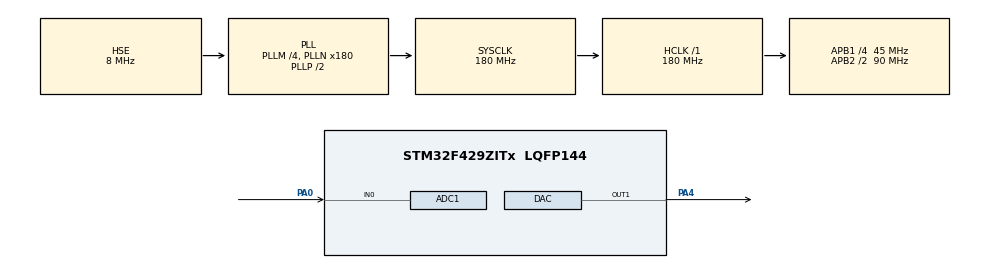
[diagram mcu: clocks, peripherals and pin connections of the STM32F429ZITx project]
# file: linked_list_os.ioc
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ADC1.Channel-0\#ChannelRegularConversion=ADC_CHANNEL_0
ADC1.DMAContinuousRequests=ENABLE
ADC1.ExternalTrigConv=ADC_EXTERNALTRIGCONV_T8_TRGO
ADC1.NbrOfConversionFlag=1
ADC1.Rank-0\#ChannelRegularConversion=1
ADC1.SamplingTime-0\#ChannelRegularConversion=ADC_SAMPLETIME_144CYCLES
ADC1.master=1
DAC.DAC_Trigger=DAC_TRIGGER_T2_TRGO
DAC.WaveGeneration=DISABLE
Dma.ADC1.0.Direction=DMA_PERIPH_TO_MEMORY
Dma.ADC1.0.FIFOMode=DMA_FIFOMODE_DISABLE
Dma.ADC1.0.Instance=DMA2_Stream0
Dma.ADC1.0.MemDataAlignment=DMA_MDATAALIGN_HALFWORD
Dma.ADC1.0.MemInc=DMA_MINC_ENABLE
Dma.ADC1.0.Mode=DMA_CIRCULAR
Dma.ADC1.0.PeriphDataAlignment=DMA_PDATAALIGN_HALFWORD
Dma.ADC1.0.PeriphInc=DMA_PINC_DISABLE
Dma.ADC1.0.Priority=DMA_PRIORITY_LOW
Dma.DAC1.1.Direction=DMA_MEMORY_TO_PERIPH
Dma.DAC1.1.FIFOMode=DMA_FIFOMODE_DISABLE
Dma.DAC1.1.Instance=DMA1_Stream5
Dma.DAC1.1.MemDataAlignment=DMA_MDATAALIGN_HALFWORD
Dma.DAC1.1.MemInc=DMA_MINC_ENABLE
Dma.DAC1.1.Mode=DMA_CIRCULAR
Dma.DAC1.1.PeriphDataAlignment=DMA_PDATAALIGN_HALFWORD
Dma.DAC1.1.PeriphInc=DMA_PINC_DISABLE
Dma.DAC1.1.Priority=DMA_PRIORITY_VERY_HIGH
Dma.Request0=ADC1
Dma.Request1=DAC1
Mcu.Family=STM32F4
Mcu.Name=STM32F429ZITx
Mcu.Package=LQFP144
NVIC.DMA1_Stream5_IRQn=true\:0\:0\:false\:false\:true\:false\:true\:true
NVIC.DMA2_Stream0_IRQn=true\:0\:0\:false\:false\:true\:false\:true\:true
NVIC.PriorityGroup=NVIC_PRIORITYGROUP_4
NVIC.TIM1_UP_TIM10_IRQn=true\:15\:0\:false\:false\:true\:false\:true\:true
NVIC.TimeBase=TIM1_UP_TIM10_IRQn
NVIC.TimeBaseIP=TIM1
PA0/WKUP.Signal=ADCx_IN0
PA13.Mode=Serial_Wire
PA13.Signal=SYS_JTMS-SWDIO
PA14.Mode=Serial_Wire
PA14.Signal=SYS_JTCK-SWCLK
PA4.Signal=COMP_DAC1_group
PH0/OSC_IN.Mode=HSE-External-Oscillator
PH0/OSC_IN.Signal=RCC_OSC_IN
PH1/OSC_OUT.Mode=HSE-External-Oscillator
PH1/OSC_OUT.Signal=RCC_OSC_OUT
ProjectManager.HeapSize=0x200
ProjectManager.StackSize=0x400
ProjectManager.TargetToolchain=STM32CubeIDE
RCC.48MHZClocksFreq_Value=90000000
RCC.AHBFreq_Value=180000000
RCC.APB1CLKDivider=RCC_HCLK_DIV4
RCC.APB1Freq_Value=45000000
RCC.APB1TimFreq_Value=90000000
RCC.APB2CLKDivider=RCC_HCLK_DIV2
RCC.APB2Freq_Value=90000000
RCC.APB2TimFreq_Value=180000000
RCC.CortexFreq_Value=180000000
RCC.HCLKFreq_Value=180000000
RCC.HSE_VALUE=8000000
RCC.HSI_VALUE=16000000
RCC.LSE_VALUE=32768
RCC.PLLM=4
RCC.PLLN=180
RCC.PLLSourceVirtual=RCC_PLLSOURCE_HSE
RCC.SYSCLKFreq_VALUE=180000000
RCC.SYSCLKSource=RCC_SYSCLKSOURCE_PLLCLK
RCC.VCOOutputFreq_Value=360000000
SH.ADCx_IN0.0=ADC1_IN0,IN0
SH.COMP_DAC1_group.0=DAC_OUT1,DAC_OUT1
TIM2.AutoReloadPreload=TIM_AUTORELOAD_PRELOAD_ENABLE
TIM2.Period=5859
TIM2.TIM_MasterOutputTrigger=TIM_TRGO_UPDATE
TIM2.TIM_MasterSlaveMode=TIM_MASTERSLAVEMODE_ENABLE
TIM8.AutoReloadPreload=TIM_AUTORELOAD_PRELOAD_ENABLE
TIM8.Period=11719
TIM8.TIM_MasterOutputTrigger=TIM_TRGO_UPDATE
TIM8.TIM_MasterSlaveMode=TIM_MASTERSLAVEMODE_ENABLE
VP_SYS_VS_tim1.Mode=TIM1
VP_TIM2_VS_ClockSourceINT.Mode=Internal
VP_TIM8_VS_ClockSourceINT.Mode=Internal
board=custom

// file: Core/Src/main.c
/* USER CODE BEGIN Header */
/**
  ******************************************************************************
  * @file           : main.c
  * @brief          : Main program body
  ******************************************************************************
  * @attention
  *
  * Copyright (c) 2022 STMicroelectronics.
  * All rights reserved.
  *
  * This software is licensed under terms that can be found in the LICENSE file
  * in the root directory of this software component.
  * If no LICENSE file comes with this software, it is provided AS-IS.
  *
  ******************************************************************************
  */
/* USER CODE END Header */
#include "main.h"

/* USER CODE BEGIN Includes */
#include "os.h"
#include "arm_const_structs.h"
/* USER CODE END Includes */

ADC_HandleTypeDef hadc1;
DMA_HandleTypeDef hdma_adc1;

DAC_HandleTypeDef hdac;
DMA_HandleTypeDef hdma_dac1;

TIM_HandleTypeDef htim2;
TIM_HandleTypeDef htim8;

void SystemClock_Config(void);
static void MX_GPIO_Init(void);
static void MX_DMA_Init(void);
static void MX_ADC1_Init(void);
static void MX_TIM8_Init(void);
static void MX_DAC_Init(void);
static void MX_TIM2_Init(void);

/* USER CODE BEGIN 0 */
#if 0
#define MEDIA_CALIB_POWER2 7
// Numero de Amostras sera 2^MEDIA_CALIB_POWER2
#define MEDIA_CALIB_SIZE (1<<MEDIA_CALIB_POWER2)
unsigned int DR1 = 0;
static void MX_ADCalibration_Init(void)
{

  ADC_MultiModeTypeDef multimode;
  ADC_ChannelConfTypeDef sConfig;

    /**Configure the global features of the ADC (Clock, Resolution, Data Alignment and number of conversion)
    */
  hadc1.Instance = ADC1;
  hadc1.Init.ClockPrescaler = ADC_CLOCK_SYNC_PCLK_DIV4;
  hadc1.Init.Resolution = ADC_RESOLUTION_12B;
  hadc1.Init.ScanConvMode = DISABLE;
  hadc1.Init.ContinuousConvMode = ENABLE;
  hadc1.Init.DiscontinuousConvMode = DISABLE;
  hadc1.Init.ExternalTrigConvEdge = ADC_EXTERNALTRIGCONVEDGE_NONE ;
  hadc1.Init.ExternalTrigConv = 0;
  hadc1.Init.DataAlign = ADC_DATAALIGN_RIGHT;
  hadc1.Init.NbrOfConversion = 1;
  hadc1.Init.DMAContinuousRequests = DISABLE;
  hadc1.Init.EOCSelection = ADC_EOC_SINGLE_CONV;
  if (HAL_ADC_Init(&hadc1) != HAL_OK)
  {
	  Error_Handler();
  }

    /**Configure the ADC multi-mode
    */
  multimode.Mode = ADC_MODE_INDEPENDENT ;
  multimode.DMAAccessMode = ADC_DMAACCESSMODE_DISABLED;
  multimode.TwoSamplingDelay = ADC_TWOSAMPLINGDELAY_5CYCLES;
  if (HAL_ADCEx_MultiModeConfigChannel(&hadc1, &multimode) != HAL_OK)
  {
	  Error_Handler();
  }

    /**Configure for the selected ADC regular channel its corresponding rank in the sequencer and its sample time.
    */
  sConfig.Channel = ADC_CHANNEL_VREFINT;
  sConfig.Rank = 1;
  sConfig.SamplingTime = ADC_SAMPLETIME_480CYCLES;
  if (HAL_ADC_ConfigChannel(&hadc1, &sConfig) != HAL_OK)
  {
	  Error_Handler();
  }

  HAL_ADC_Start(&hadc1);

  unsigned int n=0;

  for(n=0;n<MEDIA_CALIB_SIZE;n++){

	HAL_ADC_PollForConversion(&hadc1, HAL_MAX_DELAY);

	DR1 += hadc1.Instance->DR;

  }
	HAL_ADC_Stop(&hadc1);
	HAL_ADC_DeInit(&hadc1);
	DR1 = DR1 >> MEDIA_CALIB_POWER2;

}

FC=1.21/(Get_ADC_Calib());

unsigned int Get_ADC_Calib (void){
	return DR1;
}
#endif

tcb_t task1_tcb;
cpu_t task1_stk[512];

tcb_t task2_tcb;
cpu_t task2_stk[128];

uint16_t adcBuffer[256];
float ReIm[256*2];
float mod[256];
sem_t sem;

uint16_t sin_wave[256] = {2048, 2098, 2148, 2199, 2249, 2299, 2349, 2399, 2448, 2498, 2547, 2596, 2644, 2692, 2740,
		2787, 2834, 2880, 2926, 2971, 3016, 3060, 3104, 3147, 3189, 3230, 3271, 3311, 3351, 3389,
		3427, 3464, 3500, 3535, 3569, 3602, 3635, 3666, 3697, 3726, 3754, 3782, 3808, 3833, 3857,
		3880, 3902, 3923, 3943, 3961, 3979, 3995, 4010, 4024, 4036, 4048, 4058, 4067, 4074, 4081,
		4086, 4090, 4093, 4095, 4095, 4094, 4092, 4088, 4084, 4078, 4071, 4062, 4053, 4042, 4030,
		4017, 4002, 3987, 3970, 3952, 3933, 3913, 3891, 3869, 3845, 3821, 3795, 3768, 3740, 3711,
		3681, 3651, 3619, 3586, 3552, 3517, 3482, 3445, 3408, 3370, 3331, 3291, 3251, 3210, 3168,
		3125, 3082, 3038, 2994, 2949, 2903, 2857, 2811, 2764, 2716, 2668, 2620, 2571, 2522, 2473,
		2424, 2374, 2324, 2274, 2224, 2174, 2123, 2073, 2022, 1972, 1921, 1871, 1821, 1771, 1721,
		1671, 1622, 1573, 1524, 1475, 1427, 1379, 1331, 1284, 1238, 1192, 1146, 1101, 1057, 1013,
		970, 927, 885, 844, 804, 764, 725, 687, 650, 613, 578, 543, 509, 476, 444,
		414, 384, 355, 327, 300, 274, 250, 226, 204, 182, 162, 143, 125, 108, 93,
		78, 65, 53, 42, 33, 24, 17, 11, 7, 3, 1, 0, 0, 2, 5,
		9, 14, 21, 28, 37, 47, 59, 71, 85, 100, 116, 134, 152, 172, 193,
		215, 238, 262, 287, 313, 341, 369, 398, 429, 460, 493, 526, 560, 595, 631,
		668, 706, 744, 784, 824, 865, 906, 948, 991, 1035, 1079, 1124, 1169, 1215, 1261,
		1308, 1355, 1403, 1451, 1499, 1548, 1597, 1647, 1696, 1746, 1796, 1846, 1896, 1947, 1997,
		2047};

uint16_t sin_wave_3rd_harmonic[256] = {2048, 2136, 2224, 2311, 2398, 2484, 2569, 2652, 2734, 2814, 2892, 2968, 3041, 3112, 3180,
		3245, 3308, 3367, 3423, 3476, 3526, 3572, 3615, 3654, 3690, 3723, 3752, 3778, 3800, 3819,
		3835, 3848, 3858, 3866, 3870, 3872, 3871, 3869, 3864, 3857, 3848, 3838, 3827, 3814, 3801,
		3786, 3771, 3756, 3740, 3725, 3709, 3694, 3679, 3665, 3652, 3639, 3628, 3617, 3608, 3600,
		3594, 3589, 3585, 3584, 3583, 3584, 3587, 3591, 3597, 3604, 3613, 3622, 3633, 3645, 3658,
		3672, 3686, 3701, 3717, 3732, 3748, 3764, 3779, 3794, 3808, 3821, 3833, 3844, 3853, 3860,
		3866, 3870, 3872, 3871, 3868, 3862, 3854, 3842, 3828, 3810, 3789, 3765, 3738, 3707, 3673,
		3635, 3594, 3549, 3501, 3450, 3396, 3338, 3277, 3213, 3146, 3077, 3005, 2930, 2853, 2774,
		2693, 2611, 2527, 2441, 2355, 2268, 2180, 2092, 2003, 1915, 1827, 1740, 1654, 1568, 1484,
		1402, 1321, 1242, 1165, 1090, 1018, 949, 882, 818, 757, 699, 645, 594, 546, 501,
		460, 422, 388, 357, 330, 306, 285, 267, 253, 241, 233, 227, 224, 223, 225,
		229, 235, 242, 251, 262, 274, 287, 301, 316, 331, 347, 363, 378, 394, 409,
		423, 437, 450, 462, 473, 482, 491, 498, 504, 508, 511, 512, 511, 510, 506,
		501, 495, 487, 478, 467, 456, 443, 430, 416, 401, 386, 370, 355, 339, 324,
		309, 294, 281, 268, 257, 247, 238, 231, 226, 224, 223, 225, 229, 237, 247,
		260, 276, 295, 317, 343, 372, 405, 441, 480, 523, 569, 619, 672, 728, 787,
		850, 915, 983, 1054, 1127, 1203, 1281, 1361, 1443, 1526, 1611, 1697, 1784, 1871, 1959,
		2047};

void HAL_ADC_ConvCpltCallback(ADC_HandleTypeDef* hadc){
	os_sem_post(&sem);
}

volatile int counter = 0;
volatile int flag = 0;
void HAL_DAC_ConvCpltCallbackCh1(DAC_HandleTypeDef* hadc){
	counter++;
	if (counter >= 120){
		counter = 0;
		HAL_TIM_Base_Stop(&htim2);
		HAL_DAC_Stop_DMA(&hdac, DAC_CHANNEL_1);

		if (flag == 0){
			HAL_DAC_Start_DMA(&hdac, DAC_CHANNEL_1, (uint32_t*)sin_wave_3rd_harmonic, 256, DAC_ALIGN_12B_R);
			flag = 1;
		}else{
			HAL_DAC_Start_DMA(&hdac, DAC_CHANNEL_1, (uint32_t*)sin_wave, 256, DAC_ALIGN_12B_R);
			flag = 0;
		}
	    HAL_TIM_Base_Start(&htim2);
	}
}

void task1(void){
	os_sem_init(&sem);

	HAL_ADC_Start_DMA(&hadc1, (uint32_t *)adcBuffer, 256);
    HAL_DAC_Start_DMA(&hdac, DAC_CHANNEL_1, (uint32_t*)sin_wave_3rd_harmonic, 256, DAC_ALIGN_12B_R);

	HAL_TIM_Base_Start(&htim8);
    HAL_TIM_Base_Start(&htim2);

	while(1){
		os_sem_pend(&sem, 0);

		int k = 0;
		for(int i = 0; i < 256; i++){
			ReIm[k] = (float)adcBuffer[i] * 0.0007326007;
			ReIm[k+1] = 0.0;
			k += 2;
		}

		arm_cfft_f32(&arm_cfft_sR_f32_len256,ReIm,0,1);
		arm_cmplx_mag_f32(ReIm,mod,256);
		arm_scale_f32(mod, 0.0078125, mod, 128);

		volatile float fund_phase = atan2f(ReIm[3],ReIm[2])*180/M_PI;	//Fase R da harmonica fundamental
		(void)fund_phase;

	}
}

void task2(void){
	float a = 0.5, b = 1.0, c = 0.0;
	while(1){
		c = (a + b) * c;
		os_delay(10);
	}
}
/* USER CODE END 0 */

int main(void)
{

  /* MCU Configuration--------------------------------------------------------*/

  /* Reset of all peripherals, Initializes the Flash interface and the Systick. */
  HAL_Init();

  /* Configure the system clock */
  SystemClock_Config();

  /* Initialize all configured peripherals */
  MX_GPIO_Init();
  MX_DMA_Init();
  MX_ADC1_Init();
  MX_TIM8_Init();
  MX_DAC_Init();
  MX_TIM2_Init();
  /* USER CODE BEGIN 2 */
  os_install_task(&task1_tcb, task1, 10, task1_stk, 512*sizeof(cpu_t));
  os_install_task(&task2_tcb, task2, 9, task2_stk, 128*sizeof(cpu_t));

  os_start();
  /* USER CODE END 2 */

  /* Infinite loop */
  while (1)
  {

  }
}

void SystemClock_Config(void)
{
  RCC_OscInitTypeDef RCC_OscInitStruct = {0};
  RCC_ClkInitTypeDef RCC_ClkInitStruct = {0};

  /** Configure the main internal regulator output voltage
  */
  __HAL_RCC_PWR_CLK_ENABLE();
  __HAL_PWR_VOLTAGESCALING_CONFIG(PWR_REGULATOR_VOLTAGE_SCALE1);

  /** Initializes the RCC Oscillators according to the specified parameters
  * in the RCC_OscInitTypeDef structure.
  */
  RCC_OscInitStruct.OscillatorType = RCC_OSCILLATORTYPE_HSE;
  RCC_OscInitStruct.HSEState = RCC_HSE_ON;
  RCC_OscInitStruct.PLL.PLLState = RCC_PLL_ON;
  RCC_OscInitStruct.PLL.PLLSource = RCC_PLLSOURCE_HSE;
  RCC_OscInitStruct.PLL.PLLM = 4;
  RCC_OscInitStruct.PLL.PLLN = 180;
  RCC_OscInitStruct.PLL.PLLP = RCC_PLLP_DIV2;
  RCC_OscInitStruct.PLL.PLLQ = 4;
  if (HAL_RCC_OscConfig(&RCC_OscInitStruct) != HAL_OK)
  {
    Error_Handler();
  }

  /** Activate the Over-Drive mode
  */
  if (HAL_PWREx_EnableOverDrive() != HAL_OK)
  {
    Error_Handler();
  }

  /** Initializes the CPU, AHB and APB buses clocks
  */
  RCC_ClkInitStruct.ClockType = RCC_CLOCKTYPE_HCLK|RCC_CLOCKTYPE_SYSCLK
                              |RCC_CLOCKTYPE_PCLK1|RCC_CLOCKTYPE_PCLK2;
  RCC_ClkInitStruct.SYSCLKSource = RCC_SYSCLKSOURCE_PLLCLK;
  RCC_ClkInitStruct.AHBCLKDivider = RCC_SYSCLK_DIV1;
  RCC_ClkInitStruct.APB1CLKDivider = RCC_HCLK_DIV4;
  RCC_ClkInitStruct.APB2CLKDivider = RCC_HCLK_DIV2;

  if (HAL_RCC_ClockConfig(&RCC_ClkInitStruct, FLASH_LATENCY_5) != HAL_OK)
  {
    Error_Handler();
  }
}

static void MX_ADC1_Init(void)
{

  ADC_ChannelConfTypeDef sConfig = {0};

  /** Configure the global features of the ADC (Clock, Resolution, Data Alignment and number of conversion)
  */
  hadc1.Instance = ADC1;
  hadc1.Init.ClockPrescaler = ADC_CLOCK_SYNC_PCLK_DIV4;
  hadc1.Init.Resolution = ADC_RESOLUTION_12B;
  hadc1.Init.ScanConvMode = DISABLE;
  hadc1.Init.ContinuousConvMode = DISABLE;
  hadc1.Init.DiscontinuousConvMode = DISABLE;
  hadc1.Init.ExternalTrigConvEdge = ADC_EXTERNALTRIGCONVEDGE_RISING;
  hadc1.Init.ExternalTrigConv = ADC_EXTERNALTRIGCONV_T8_TRGO;
  hadc1.Init.DataAlign = ADC_DATAALIGN_RIGHT;
  hadc1.Init.NbrOfConversion = 1;
  hadc1.Init.DMAContinuousRequests = ENABLE;
  hadc1.Init.EOCSelection = ADC_EOC_SINGLE_CONV;
  if (HAL_ADC_Init(&hadc1) != HAL_OK)
  {
    Error_Handler();
  }

  /** Configure for the selected ADC regular channel its corresponding rank in the sequencer and its sample time.
  */
  sConfig.Channel = ADC_CHANNEL_0;
  sConfig.Rank = 1;
  sConfig.SamplingTime = ADC_SAMPLETIME_144CYCLES;
  if (HAL_ADC_ConfigChannel(&hadc1, &sConfig) != HAL_OK)
  {
    Error_Handler();
  }

}

static void MX_DAC_Init(void)
{

  DAC_ChannelConfTypeDef sConfig = {0};

  /** DAC Initialization
  */
  hdac.Instance = DAC;
  if (HAL_DAC_Init(&hdac) != HAL_OK)
  {
    Error_Handler();
  }

  /** DAC channel OUT1 config
  */
  sConfig.DAC_Trigger = DAC_TRIGGER_T2_TRGO;
  sConfig.DAC_OutputBuffer = DAC_OUTPUTBUFFER_ENABLE;
  if (HAL_DAC_ConfigChannel(&hdac, &sConfig, DAC_CHANNEL_1) != HAL_OK)
  {
    Error_Handler();
  }

}

static void MX_TIM2_Init(void)
{

  TIM_ClockConfigTypeDef sClockSourceConfig = {0};
  TIM_MasterConfigTypeDef sMasterConfig = {0};

  htim2.Instance = TIM2;
  htim2.Init.Prescaler = 0;
  htim2.Init.CounterMode = TIM_COUNTERMODE_UP;
  htim2.Init.Period = 5859;
  htim2.Init.ClockDivision = TIM_CLOCKDIVISION_DIV1;
  htim2.Init.AutoReloadPreload = TIM_AUTORELOAD_PRELOAD_ENABLE;
  if (HAL_TIM_Base_Init(&htim2) != HAL_OK)
  {
    Error_Handler();
  }
  sClockSourceConfig.ClockSource = TIM_CLOCKSOURCE_INTERNAL;
  if (HAL_TIM_ConfigClockSource(&htim2, &sClockSourceConfig) != HAL_OK)
  {
    Error_Handler();
  }
  sMasterConfig.MasterOutputTrigger = TIM_TRGO_UPDATE;
  sMasterConfig.MasterSlaveMode = TIM_MASTERSLAVEMODE_ENABLE;
  if (HAL_TIMEx_MasterConfigSynchronization(&htim2, &sMasterConfig) != HAL_OK)
  {
    Error_Handler();
  }

}

static void MX_TIM8_Init(void)
{

  TIM_ClockConfigTypeDef sClockSourceConfig = {0};
  TIM_MasterConfigTypeDef sMasterConfig = {0};

  htim8.Instance = TIM8;
  htim8.Init.Prescaler = 0;
  htim8.Init.CounterMode = TIM_COUNTERMODE_UP;
  htim8.Init.Period = 11719;
  htim8.Init.ClockDivision = TIM_CLOCKDIVISION_DIV1;
  htim8.Init.RepetitionCounter = 0;
  htim8.Init.AutoReloadPreload = TIM_AUTORELOAD_PRELOAD_ENABLE;
  if (HAL_TIM_Base_Init(&htim8) != HAL_OK)
  {
    Error_Handler();
  }
  sClockSourceConfig.ClockSource = TIM_CLOCKSOURCE_INTERNAL;
  if (HAL_TIM_ConfigClockSource(&htim8, &sClockSourceConfig) != HAL_OK)
  {
    Error_Handler();
  }
  sMasterConfig.MasterOutputTrigger = TIM_TRGO_UPDATE;
  sMasterConfig.MasterSlaveMode = TIM_MASTERSLAVEMODE_ENABLE;
  if (HAL_TIMEx_MasterConfigSynchronization(&htim8, &sMasterConfig) != HAL_OK)
  {
    Error_Handler();
  }

}

static void MX_DMA_Init(void)
{

  /* DMA controller clock enable */
  __HAL_RCC_DMA2_CLK_ENABLE();
  __HAL_RCC_DMA1_CLK_ENABLE();

  /* DMA interrupt init */
  /* DMA1_Stream5_IRQn interrupt configuration */
  HAL_NVIC_SetPriority(DMA1_Stream5_IRQn, 0, 0);
  HAL_NVIC_EnableIRQ(DMA1_Stream5_IRQn);
  /* DMA2_Stream0_IRQn interrupt configuration */
  HAL_NVIC_SetPriority(DMA2_Stream0_IRQn, 0, 0);
  HAL_NVIC_EnableIRQ(DMA2_Stream0_IRQn);

}

static void MX_GPIO_Init(void)
{

  /* GPIO Ports Clock Enable */
  __HAL_RCC_GPIOH_CLK_ENABLE();
  __HAL_RCC_GPIOA_CLK_ENABLE();

}

void HAL_TIM_PeriodElapsedCallback(TIM_HandleTypeDef *htim)
{
  if (htim->Instance == TIM1) {
    HAL_IncTick();
  }
}

void Error_Handler(void)
{
  __disable_irq();
  while (1)
  {
  }
}
